# DA14531 register map
Vendor: Dialog; Series: DA14531; File version: 1.2
CPU: CM0 r1p0, little endian, MPU, FPU, 3 interrupt priority bits
Registers are 16-bit, read-write, reset 0x0 unless marked. A register's access mark holds for its fields unless they carry their own. Offsets are from the block's base; [hi:lo] are bit positions; {n}, {i} and the like mark numbered series.

## GPREG — GPREG registers
Base 0x50003300
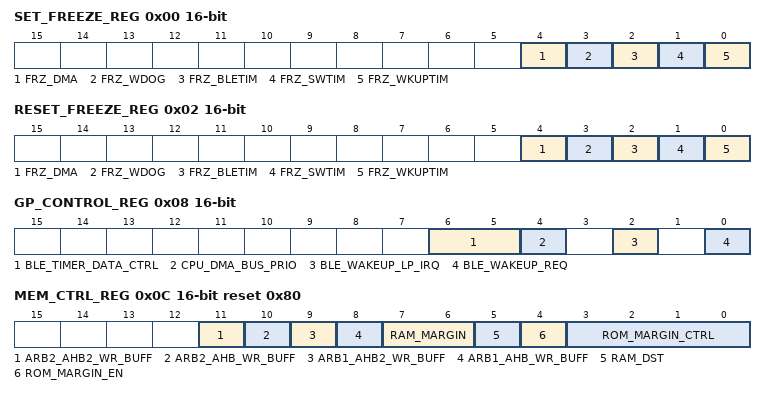
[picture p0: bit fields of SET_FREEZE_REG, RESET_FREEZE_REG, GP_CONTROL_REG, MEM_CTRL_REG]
0x00 SET_FREEZE_REG — Controls freezing of various timers/counters.
  [4] FRZ_DMA — If '1', the DMA is frozen, '0' is discarded.
  [3] FRZ_WDOG — If '1', the watchdog timer is frozen, '0' is discarded. WATCHDOG_CTRL_REG[NMI_RST] must be '0' to allow the freeze function.
  [2] FRZ_BLETIM — If '1', the BLE master clock is frozen, '0' is discarded.
  [1] FRZ_SWTIM — If '1', the SW Timer (TIMER0) is frozen, '0' is discarded.
  [0] FRZ_WKUPTIM — If '1', the Wake Up Timer is frozen, '0' is discarded.
0x02 RESET_FREEZE_REG — Controls unfreezing of various timers/counters.
  [4] FRZ_DMA — If '1', the DMA continues, '0' is discarded.
  [3] FRZ_WDOG — If '1', the watchdog timer continues, '0' is discarded.
  [2] FRZ_BLETIM — If '1', the the BLE master clock continues, '0' is discarded.
  [1] FRZ_SWTIM — If '1', the SW Timer (TIMER0) continues, '0' is discarded.
  [0] FRZ_WKUPTIM — If '1', the Wake Up Timer continues, '0' is discarded.
0x04 DEBUG_REG reset 0x1 — Various debug information register.
  [0] DEBUGS_FREEZE_EN — Default '1', freezing of the on-chip timers is enabled when the Cortex-M0Plus is halted in DEBUG State. If '0', freezing of the on-chip timers is depending on FREEZE_REG when the Cortex-M0Plus is halted in DEBUG State except the watchdog timer. The watchdog timer is always frozen when the Cortex-M0Plus is halted in DEBUG State.
0x06 GP_STATUS_REG — General purpose system status register.
  [0] CAL_PHASE — If '1', it designates that the chip is in Calibration Phase i.e. the OTP has been initially programmed but no Calibration has occured.
0x08 GP_CONTROL_REG — General purpose system control register.
  [6:5] BLE_TIMER_DATA_CTRL — Refer to BLE_TIMER_REG.
  [4] CPU_DMA_BUS_PRIO — Controls the CPU DMA system bus priority: If '0', the CPU has highest priority. If '1', the DMA has highest priority.
  [2] BLE_WAKEUP_LP_IRQ ro — The current value of the BLE_WAKEUP_LP_IRQ interrupt request.
  [0] BLE_WAKEUP_REQ — If '1', the BLE wakes up. Must be kept high at least for 1 low power clock period. If the BLE is in deep sleep state, then by setting this bit it will cause the wakeup LP IRQ to be asserted with a delay of 3 to 4 low power cycles.
0x0A BLE_TIMER_REG — BLE FINECNT sampled value while in deep sleep state.
  [9:0] BLE_TIMER_DATA — Operation depends on GP_CONTROL_REG->BLE_TIMER_DATA_CTRL. If BLE_TIMER_DATA_CTRL = 0 then: This register is located at the Always On Power Domain and it holds the automatically sampled value of the BLE FINECNT timer The HW automatically samples the value into this register during the sequence of "BLE Sleep On" and restores automatically the value during the BLE Wake up sequence. The Software may read and modify the value while the BLE is in Sleep state. While the BLE is awake, the value of the register has no meaning, while changing the value by writing another one will have no effect in the operation of the BLE core. There is a constraint when the SW performs an write-read sequence where it has to inject a one cycle delay in between (e.g. write-NOP-read) in order to read back the correct value. If BLE_TIMER_DATA_CTRL is non 0 then write operations have the same effect as when BLE_TIMER_DATA_CTRL=0, while for read operations: BLE_TIMER_DATA_CTRL= 1: then reading BLE_TIMER_REG returns "deepsldur[9:0]". BLE_TIMER_DATA_CTRL= 2: then reading BLE_TIMER_REG returns "deepsltime_samp[9:0]". BLE_TIMER_DATA_CTRL= 3: then reading BLE_TIMER_REG returns "{deep_sleep_stat_monitor, deepsltime_samp[18:10]}. .
0x0C MEM_CTRL_REG reset 0x80
  [11] ARB2_AHB2_WR_BUFF ro, [10] ARB2_AHB_WR_BUFF ro, [9] ARB1_AHB2_WR_BUFF ro, [8] ARB1_AHB_WR_BUFF ro, [7:6] RAM_MARGIN, [5] RAM_DST, [4] ROM_MARGIN_EN, [3:0] ROM_MARGIN_CTRL
